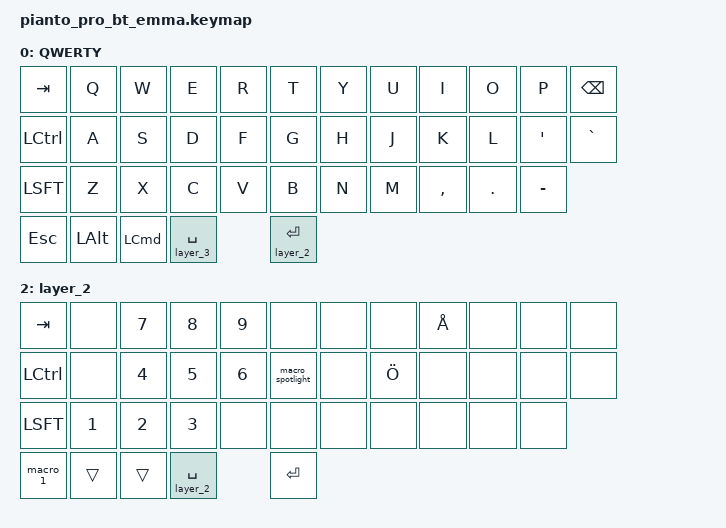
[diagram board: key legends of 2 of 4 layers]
/ {
    macros {
        macro_spotlight: macro_spotlight {
            bindings = <
                &kp LCMD &kp SPACE
            >;
        };
        macro_1: macro_1 {
            // TODO: define your macro here
            bindings = <&none>;
        };
    };
};

#include <behaviors.dtsi>
#include <dt-bindings/zmk/keys.h>
#include <dt-bindings/zmk/bt.h>
#include <dt-bindings/zmk/rgb.h>

/ {
    chosen {
        zmk,physical-layout = &default_layout;
    };
};

/ {
    keymap {
        compatible = "zmk,keymap";

        /* ======================= DEFAULT LAYER ======================= */
        default_layer {
            display-name = "QWERTY";
            bindings = <
                // Row 1
                &kp TAB   &kp Q    &kp W    &kp E    &kp R    &kp T        &kp Y    &kp U    &kp I    &kp O    &kp P    &kp BSPC
                // Row 2
                &kp LCTL  &kp A    &kp S    &kp D    &kp F    &kp G        &kp H    &kp J    &kp K    &kp L    &kp QUOT &kp GRAVE
                // Row 3
                &kp LSFT  &kp Z    &kp X    &kp C    &kp V    &kp B        &kp N    &kp M    &kp COMMA &kp DOT &kp MINUS
                // Thumbs
                &kp ESC   &kp LALT &kp LCMD &lt layer_3 SPACE  &lt layer_2 ENTER
            >;
        };

        /* ======================= LAYER 1 ======================= */
        layer_1 {
            bindings = <
                // Row 1
                &kp PLUS &kp N1 &kp N2 &kp N3 &kp N4 &kp N5     &kp N6 &kp N7 &kp N8 &kp N9 &kp N0 &kp BSPC
                // Row 2
                &kp LCTL &none   &kp LT &kp GT &kp PLUS &kp CARET    &kp LEFT &kp DOWN &kp UP &kp RIGHT &none &none
                // Row 3
                &kp LSFT &kp Z   &kp X  &kp C  &kp V  &kp B        &kp OSL(layer_1) &kp OSL(layer_2) &kp SPC &kp ENTER
                // Thumbs
                &trans &trans
            >;
        };

        /* ======================= LAYER 2 ======================= */
        layer_2 {
            bindings = <
                // Row 1
                &kp TAB &none &kp N7 &kp N8 &kp N9 &none       &none &none &kp Å &none &none &none
                // Row 2
                &kp LCTL &none &kp N4 &kp N5 &kp N6 &macro_spotlight   &none &kp Ö &none &none &none &none
                // Row 3
                &kp LSFT &kp N1 &kp N2 &kp N3 &none &none      &none &none &none &none &none
                // Thumbs
                &macro_1 &trans &trans &lt layer_2 SPACE &kp ENTER
            >;
        };

        /* ======================= LAYER 3 ======================= */
        layer_3 {
            bindings = <
                // Row 1
                &reset &none &none &none &none &msc WH_D       &kp MPRV &kp MPLY &kp MNXT &kp VOL_DN &none &none
                // Row 2
                &kp VOL_UP &kp MUTE &rgb MODE_NEXT &rgb HUI &rgb VAI &msc BTN3  &msc BTN2 &msc BTN1 &msc LEFT &msc DOWN &none &none
                // Row 3
                &msc UP &msc RIGHT &msc WH_DOWN &none &rgb TOG &rgb HUD &rgb VAD &none &msc WH_UP &none &none
                // Thumbs
                &msc BTN1 &msc BTN2 &msc BTN3 &msc WH_UP &kp ESC &trans &trans &kp SPACE &kp ENTER
            >;
        };
    };
};
